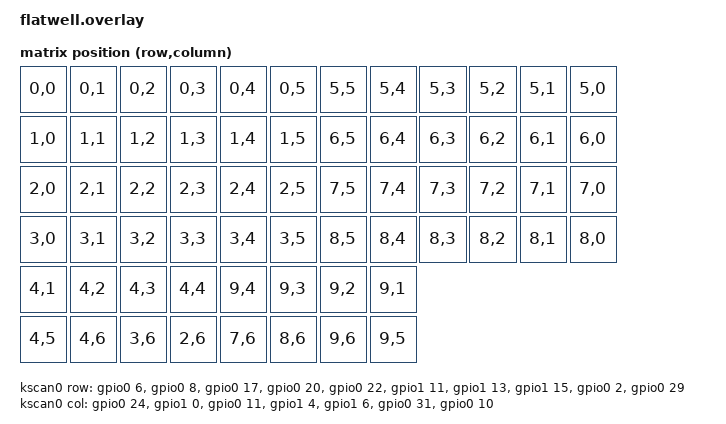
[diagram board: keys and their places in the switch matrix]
// Generated by scripts/zmk.mjs. Edit that (or ergogen/config.yaml), not this file.

#include <dt-bindings/zmk/matrix_transform.h>
#include "flatwell-layouts.dtsi"

// C6 uses an NFC antenna pin (P0.09/P0.10) as a plain GPIO.
&uicr {
    nfct-pins-as-gpios;
};

/ {
    chosen {
        zmk,physical-layout = &physical_layout0;
    };

    // 10 rows x 7 columns, col2row: column -> switch -> diode -> row.
    // Rows R0-R4 are the left half, R5-R9 the right.
    kscan0: kscan0 {
        compatible = "zmk,kscan-gpio-matrix";
        diode-direction = "col2row";
        wakeup-source;

        row-gpios  // R0 R1 R2 R3 R4 R5 R6 R7 R8 R9
            = <&gpio0 6 (GPIO_ACTIVE_HIGH | GPIO_PULL_DOWN)>
            , <&gpio0 8 (GPIO_ACTIVE_HIGH | GPIO_PULL_DOWN)>
            , <&gpio0 17 (GPIO_ACTIVE_HIGH | GPIO_PULL_DOWN)>
            , <&gpio0 20 (GPIO_ACTIVE_HIGH | GPIO_PULL_DOWN)>
            , <&gpio0 22 (GPIO_ACTIVE_HIGH | GPIO_PULL_DOWN)>
            , <&gpio1 11 (GPIO_ACTIVE_HIGH | GPIO_PULL_DOWN)>
            , <&gpio1 13 (GPIO_ACTIVE_HIGH | GPIO_PULL_DOWN)>
            , <&gpio1 15 (GPIO_ACTIVE_HIGH | GPIO_PULL_DOWN)>
            , <&gpio0 2 (GPIO_ACTIVE_HIGH | GPIO_PULL_DOWN)>
            , <&gpio0 29 (GPIO_ACTIVE_HIGH | GPIO_PULL_DOWN)>
            ;
        col-gpios  // C0 C1 C2 C3 C4 C5 C6
            = <&gpio0 24 GPIO_ACTIVE_HIGH>
            , <&gpio1 0 GPIO_ACTIVE_HIGH>
            , <&gpio0 11 GPIO_ACTIVE_HIGH>
            , <&gpio1 4 GPIO_ACTIVE_HIGH>
            , <&gpio1 6 GPIO_ACTIVE_HIGH>
            , <&gpio0 31 GPIO_ACTIVE_HIGH>
            , <&gpio0 10 GPIO_ACTIVE_HIGH>
            ;
    };

    default_transform: keymap_transform0 {
        compatible = "zmk,matrix-transform";
        rows = <10>;
        columns = <7>;
        map = <
            RC(0,0) RC(0,1) RC(0,2) RC(0,3) RC(0,4) RC(0,5) RC(5,5) RC(5,4) RC(5,3) RC(5,2) RC(5,1) RC(5,0)
            RC(1,0) RC(1,1) RC(1,2) RC(1,3) RC(1,4) RC(1,5) RC(6,5) RC(6,4) RC(6,3) RC(6,2) RC(6,1) RC(6,0)
            RC(2,0) RC(2,1) RC(2,2) RC(2,3) RC(2,4) RC(2,5) RC(7,5) RC(7,4) RC(7,3) RC(7,2) RC(7,1) RC(7,0)
            RC(3,0) RC(3,1) RC(3,2) RC(3,3) RC(3,4) RC(3,5) RC(8,5) RC(8,4) RC(8,3) RC(8,2) RC(8,1) RC(8,0)
            RC(4,1) RC(4,2) RC(4,3) RC(4,4) RC(9,4) RC(9,3) RC(9,2) RC(9,1)
            RC(4,5) RC(4,6) RC(3,6) RC(2,6) RC(7,6) RC(8,6) RC(9,6) RC(9,5)
        >;
    };
};
